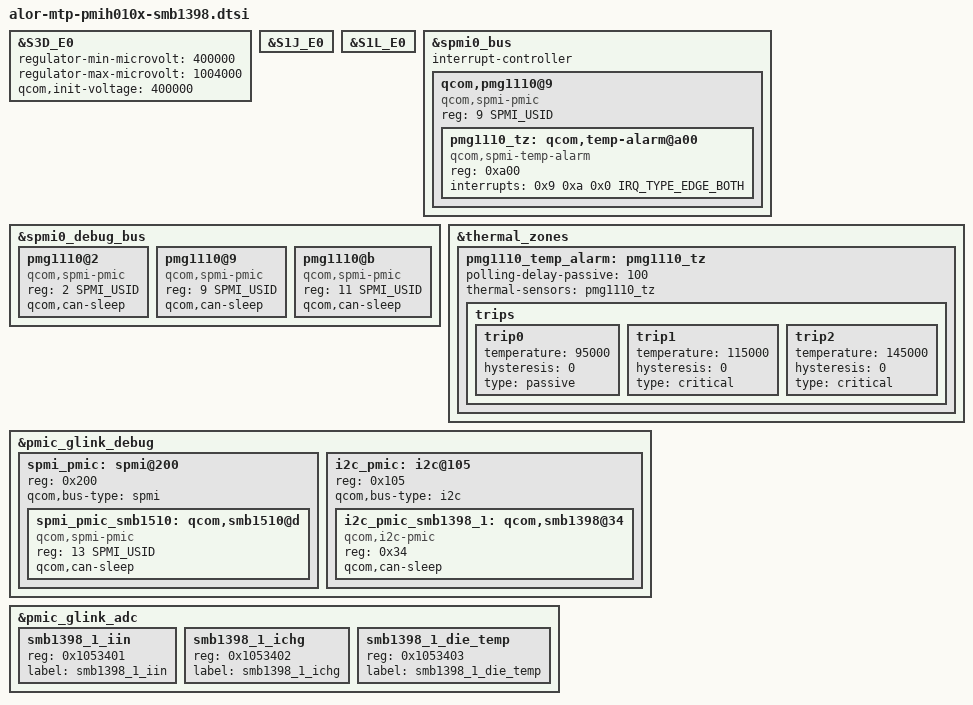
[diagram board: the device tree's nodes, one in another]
// SPDX-License-Identifier: BSD-3-Clause
/*
 * Copyright (c) Qualcomm Technologies, Inc. and/or its subsidiaries.
 */

#include "alor-mtp.dtsi"
#include "alor-pmih010x-pmd802x.dtsi"

&S3D_E0 {
	regulator-min-microvolt = <400000>;
	regulator-max-microvolt = <1004000>;
	qcom,init-voltage = <400000>;
};

&S1J_E0 {
	status = "ok";
};

&S1L_E0 {
	status = "ok";
};

&spmi0_bus {
	#address-cells = <2>;
	#size-cells = <0>;
	interrupt-controller;
	#interrupt-cells = <4>;

	qcom,pmg1110@9 {
		compatible = "qcom,spmi-pmic";
		reg = <9 SPMI_USID>;
		#address-cells = <1>;
		#size-cells = <0>;

		pmg1110_tz: qcom,temp-alarm@a00 {
			compatible = "qcom,spmi-temp-alarm";
			reg = <0xa00>;
			interrupts = <0x9 0xa 0x0 IRQ_TYPE_EDGE_BOTH>;
			#thermal-sensor-cells = <0>;
		};
	};
};

&spmi0_debug_bus {
	pmg1110@2 {
		compatible = "qcom,spmi-pmic";
		reg = <2 SPMI_USID>;
		#address-cells = <2>;
		#size-cells = <0>;
		qcom,can-sleep;
	};

	pmg1110@9 {
		compatible = "qcom,spmi-pmic";
		reg = <9 SPMI_USID>;
		#address-cells = <2>;
		#size-cells = <0>;
		qcom,can-sleep;
	};

	pmg1110@b {
		compatible = "qcom,spmi-pmic";
		reg = <11 SPMI_USID>;
		#address-cells = <2>;
		#size-cells = <0>;
		qcom,can-sleep;
	};
};

&thermal_zones {
	pmg1110_temp_alarm: pmg1110_tz {
		polling-delay-passive = <100>;
		thermal-sensors = <&pmg1110_tz>;

		trips {
			trip0 {
				temperature = <95000>;
				hysteresis = <0>;
				type = "passive";
			};

			trip1 {
				temperature = <115000>;
				hysteresis = <0>;
				type = "critical";
			};

			trip2 {
				temperature = <145000>;
				hysteresis = <0>;
				type = "critical";
			};
		};
	};
};

&pmic_glink_debug {
	/* SPMI bridge bus 1 with SMB1510 device */
	spmi_pmic:spmi@200 {
		reg = <0x200>;
		#address-cells = <2>;
		#size-cells = <0>;
		qcom,bus-type = "spmi";

		spmi_pmic_smb1510: qcom,smb1510@d {
			compatible = "qcom,spmi-pmic";
			reg = <13 SPMI_USID>;
			qcom,can-sleep;
		};
	};

	i2c_pmic:i2c@105 {
		reg = <0x105>;  /* I2C instance 5 in ADSP for SE4 */
		#address-cells = <1>;
		#size-cells = <0>;
		qcom,bus-type = "i2c";

		i2c_pmic_smb1398_1: qcom,smb1398@34 {
			compatible = "qcom,i2c-pmic";
			reg = <0x34>;
			qcom,can-sleep;
		};
	};
};

&pmic_glink_adc {
	status = "ok";

	smb1398_1_iin {
		reg = <0x1053401>;
		label = "smb1398_1_iin";
	};

	smb1398_1_ichg {
		reg = <0x1053402>;
		label = "smb1398_1_ichg";
	};

	smb1398_1_die_temp {
		reg = <0x1053403>;
		label = "smb1398_1_die_temp";
	};
};
